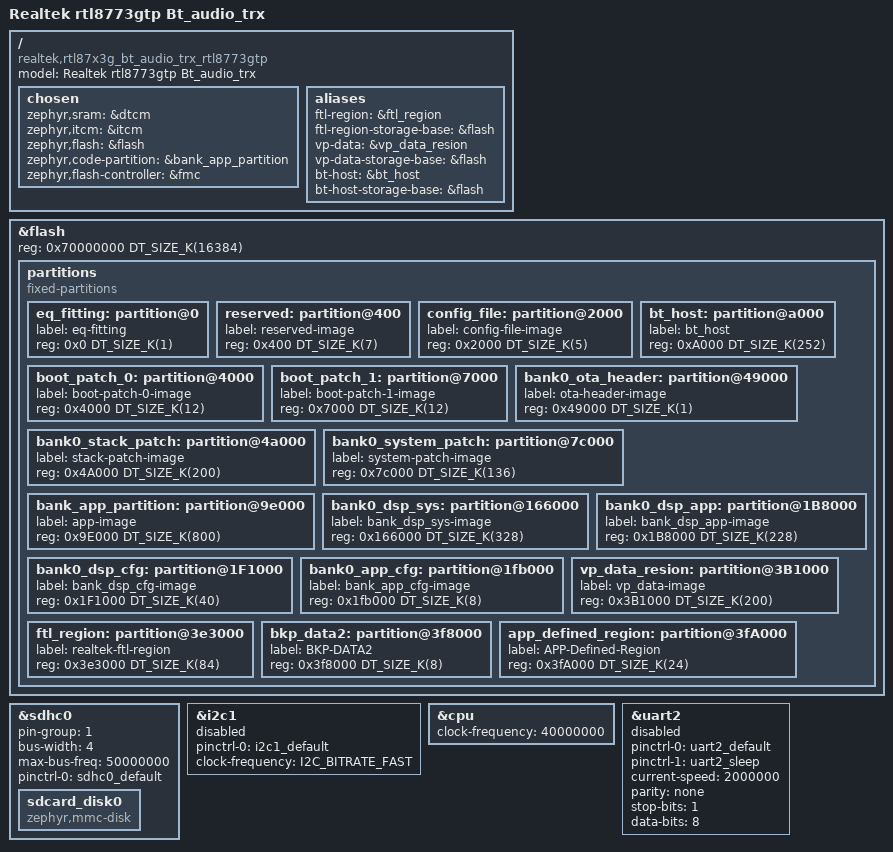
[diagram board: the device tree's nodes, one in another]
/*
 * Copyright (c) 2026, Realtek Semiconductor Corporation
 *
 * SPDX-License-Identifier: LicenseRef-Realtek-5-Clause
 */

/dts-v1/;
#include <realtek/rtl87x3g.dtsi>
#include "rtl87x3g_bt_audio_trx_rtl8763gws-pinctrl.dtsi"
#include "board_pin_assignments/rtl8763gws/board.h"
/ {
	model = "Realtek rtl8773gtp Bt_audio_trx";
	compatible = "realtek,rtl87x3g_bt_audio_trx_rtl8773gtp";
	chosen {
		zephyr,sram = &dtcm;
		zephyr,itcm = &itcm;
		zephyr,flash = &flash;
		zephyr,code-partition = &bank_app_partition;
//		zephyr,console = &uart2;
//		zephyr,shell-uart = &uart2;
		zephyr,flash-controller = &fmc;
	};
	/* These aliases are used by soc.c */
	aliases {
		ftl-region = &ftl_region;
		ftl-region-storage-base = &flash;
		vp-data = &vp_data_resion;
		vp-data-storage-base = &flash;
		bt-host = &bt_host;
		bt-host-storage-base = &flash;
	};
	/*	psram0:psram0 {
		#address-cells = <1>;
		#size-cells = <1>;
		psram0_for_mcu: memory@22000000{
			device_type = "psram 0 region";
			reg = <0x22000000 DT_SIZE_K(4096)>;
		};
	};
	*/

};


&flash
{
	reg = <0x70000000 DT_SIZE_K(16384)>;
	partitions {
	compatible = "fixed-partitions";
		#address-cells = <1>;
		#size-cells = <1>;
		eq_fitting: partition@0 {
			label = "eq-fitting";
			reg = <0x0 DT_SIZE_K(1)>;
		};
		reserved: partition@400 {
			label = "reserved-image";
			reg = <0x400 DT_SIZE_K(7)>;
		};
		config_file: partition@2000 {
			label = "config-file-image";
			reg = <0x2000 DT_SIZE_K(5)>;
		};
		boot_patch_0: partition@4000 {
			label = "boot-patch-0-image";
			reg = <0x4000 DT_SIZE_K(12)>;
		};
		boot_patch_1: partition@7000 {
			label = "boot-patch-1-image";
			reg = <0x7000 DT_SIZE_K(12)>;
		};
		bt_host: partition@a000 {
			label = "bt_host";
			reg = <0xA000 DT_SIZE_K(252)>;
		};
		bank0_ota_header: partition@49000 {
			label = "ota-header-image";
			reg = <0x49000 DT_SIZE_K(1)>;
		};
		bank0_stack_patch: partition@4a000 {
			label = "stack-patch-image";
			reg = <0x4A000 DT_SIZE_K(200)>;
		};
		bank0_system_patch: partition@7c000 {
			label = "system-patch-image";
			reg = <0x7c000 DT_SIZE_K(136)>;
		};
		bank_app_partition: partition@9e000 {
			label = "app-image";
			reg = <0x9E000 DT_SIZE_K(800)>;
		};
		bank0_dsp_sys: partition@166000 {
			label = "bank_dsp_sys-image";
			reg = <0x166000 DT_SIZE_K(328)>;
		};
		bank0_dsp_app: partition@1B8000 {
			label = "bank_dsp_app-image";
			reg = <0x1B8000 DT_SIZE_K(228)>;
		};
		bank0_dsp_cfg: partition@1F1000 {
			label = "bank_dsp_cfg-image";
			reg = <0x1F1000 DT_SIZE_K(40)>;
		};
		bank0_app_cfg: partition@1fb000 {
			label = "bank_app_cfg-image";
			reg = <0x1fb000 DT_SIZE_K(8)>;
		};
		vp_data_resion: partition@3B1000 {
			label = "vp_data-image";
			reg = <0x3B1000 DT_SIZE_K(200)>;
		};
		
		ftl_region: partition@3e3000 {
			label = "realtek-ftl-region";
			reg = <0x3e3000 DT_SIZE_K(84)>; 
		};
		
		bkp_data2: partition@3f8000 {
			label = "BKP-DATA2";
			reg = <0x3f8000 DT_SIZE_K(8)>;
		};
		
		app_defined_region: partition@3fA000 {
			label = "APP-Defined-Region";
			reg = <0x3fA000 DT_SIZE_K(24)>;
		};
	};
};

&sdhc0 {
    pin-group = <1>;
    bus-width = <4>;
	max-bus-freq = <50000000>;
	/*P3_4       26  /*!< GPIOA6 */ 
    pinctrl-0 = <&sdhc0_default>;
    pinctrl-names = "default";
    status = "ok";
	sdcard_disk0: sdcard_disk0 {
		//compatible = "zephyr,sdmmc-disk";
		compatible = "zephyr,mmc-disk";
		status = "ok";
	};
};

&i2c1 {
	pinctrl-0 = <&i2c1_default>;
    pinctrl-names = "default";
	clock-frequency = <I2C_BITRATE_FAST>;
	status = "disabled";
};

&cpu {
	clock-frequency = <40000000>;
};

&uart2 {
	pinctrl-0 = <&uart2_default>;
	pinctrl-1 = <&uart2_sleep>;
	pinctrl-names = "default", "sleep";
	status = "disabled";
	current-speed = <2000000>;
	parity = "none";
	stop-bits = "1";
	data-bits = <8>;
};
